# YTM32B1ME0 register map
Vendor: YTMicro; File version: 1.6
CPU: CM33 r0p4, little endian, MPU, FPU, 2 interrupt priority bits
Registers are 32-bit, read-write, reset 0x0 unless marked. A register's access mark holds for its fields unless they carry their own. Offsets are from the block's base; [hi:lo] are bit positions; {n}, {i} and the like mark numbered series; 'fields as' and 'values as' point back to an identical list.

## CAN0 (part 4 of 4) — FlexCAN module
Base 0x40030000; register names take the prefix CAN0_
0x974 RXIMR61 — The RX Individual Mask Registers are used to store the acceptance masks for ID filtering in Rx MBs and the Legacy Rx FIFO. When the Legacy Rx FIFO is disabled (CAN_MCR.RFEN is negated), an individual mask is provided for each available Rx mailbox on a one-to-one correspondence. When the Legacy Rx FIFO is enabled (CAN_MCR.RFEN is asserted), an individual mask is provided for each Legacy Rx FIFO ID Filter Table Element on a one-to-one correspondence depending on the setting of $ ewline$ CAN_CTRL2.RFFN (see \hyperref[legacy-rx-fifo]{"Legacy Rx FIFO"}). CAN_RXIMR0 stores the individual mask associated with either MB0 or ID Filter Table Element 0, CAN_RXIMR1 stores the individual mask associated with either MB1 or ID Filter Table Element 1, and so on. CAN_RXIMRn registers can only be accessed by the CPU when the FlexCAN is in Freeze mode; otherwise, they are blocked by hardware. The CAN_RXIMRn registers are not affected by reset. They are located in RAM and must be explicitly initialized prior to any reception. The CAN_RXIMRn registers are not available if parameter IRMQ_EN is 0.
  [31:0] MI — Each Individual Mask Bit masks the corresponding bit in both the mailbox filter and Legacy Rx FIFO ID Filter Table element in distinct ways. For mailbox filters, see the RXMGMASK register description. For Legacy Rx FIFO ID Filter Table elements, see the RXFGMASK register description. 0b - The corresponding bit in the filter is ``don't care". 1b - The corresponding bit in the filter is checked.
0x978 RXIMR62 — The RX Individual Mask Registers are used to store the acceptance masks for ID filtering in Rx MBs and the Legacy Rx FIFO. When the Legacy Rx FIFO is disabled (CAN_MCR.RFEN is negated), an individual mask is provided for each available Rx mailbox on a one-to-one correspondence. When the Legacy Rx FIFO is enabled (CAN_MCR.RFEN is asserted), an individual mask is provided for each Legacy Rx FIFO ID Filter Table Element on a one-to-one correspondence depending on the setting of $ ewline$ CAN_CTRL2.RFFN (see \hyperref[legacy-rx-fifo]{"Legacy Rx FIFO"}). CAN_RXIMR0 stores the individual mask associated with either MB0 or ID Filter Table Element 0, CAN_RXIMR1 stores the individual mask associated with either MB1 or ID Filter Table Element 1, and so on. CAN_RXIMRn registers can only be accessed by the CPU when the FlexCAN is in Freeze mode; otherwise, they are blocked by hardware. The CAN_RXIMRn registers are not affected by reset. They are located in RAM and must be explicitly initialized prior to any reception. The CAN_RXIMRn registers are not available if parameter IRMQ_EN is 0.
  fields as RXIMR61
0x97C RXIMR63 — The RX Individual Mask Registers are used to store the acceptance masks for ID filtering in Rx MBs and the Legacy Rx FIFO. When the Legacy Rx FIFO is disabled (CAN_MCR.RFEN is negated), an individual mask is provided for each available Rx mailbox on a one-to-one correspondence. When the Legacy Rx FIFO is enabled (CAN_MCR.RFEN is asserted), an individual mask is provided for each Legacy Rx FIFO ID Filter Table Element on a one-to-one correspondence depending on the setting of $ ewline$ CAN_CTRL2.RFFN (see \hyperref[legacy-rx-fifo]{"Legacy Rx FIFO"}). CAN_RXIMR0 stores the individual mask associated with either MB0 or ID Filter Table Element 0, CAN_RXIMR1 stores the individual mask associated with either MB1 or ID Filter Table Element 1, and so on. CAN_RXIMRn registers can only be accessed by the CPU when the FlexCAN is in Freeze mode; otherwise, they are blocked by hardware. The CAN_RXIMRn registers are not affected by reset. They are located in RAM and must be explicitly initialized prior to any reception. The CAN_RXIMRn registers are not available if parameter IRMQ_EN is 0.
  fields as RXIMR61
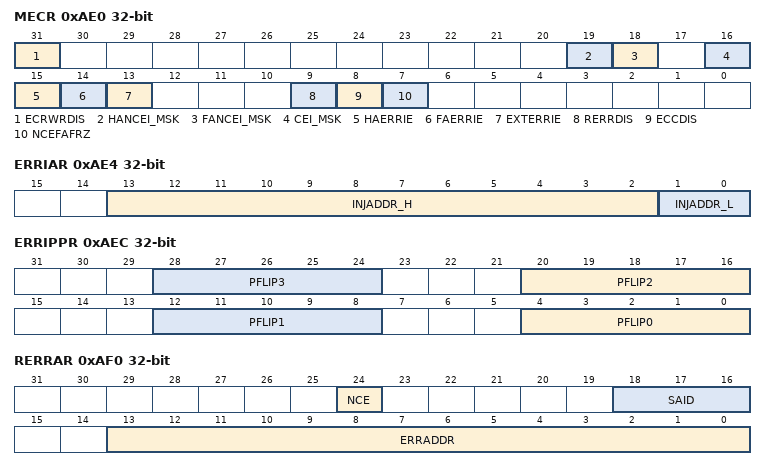
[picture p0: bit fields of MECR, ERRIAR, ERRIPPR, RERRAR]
0xAE0 MECR — The CAN_MECR register contains control bits for memory error detection and correction (ECC). NOTE: When CAN_CTRL2.ECRWRE is 0, writes to CAN_MECR are blocked, with the exception of the ECRWRDIS bit.
  [31] ECRWRDIS — ECRWRDIS is automatically set to 1 (disabled) when CTRL2.ECRWRE is asserted. The protocol described in \hyperref[detection-and-correction-of-memory-errors]{"Detection and Correction of Memory Errors"} must be followed.
    0=Write is enabled; 1=Write is disabled
  [19] HANCEI_MSK — Enables the interrupt in case of non-correctable errors detected in memory reads issued by the host (CPU).
    0=Interrupt is disabled; 1=Interrupt is enabled
  [18] FANCEI_MSK — Enables the interrupt in case of non-correctable errors detected in memory reads issued by the FlexCAN internal processes.
    0=Interrupt is disabled; 1=Interrupt is enabled
  [16] CEI_MSK — Enables the interrupt in case of correctable errors detected in memory reads issued by the host or FlexCAN internal processes.
    0=Interrupt is disabled; 1=Interrupt is enabled
  [15] HAERRIE — Enables the injection of errors only in memory reads issued by the host (CPU).
    0=Interrupt is disabled; 1=Interrupt is enabled
  [14] FAERRIE — Enables the injection of errors only in memory reads issued by the FlexCAN internal processes.
    0=Interrupt is disabled; 1=Interrupt is enabled
  [13] EXTERRIE — Memory accesses performed by internal FlexCAN processes are 64-bit accesses. EXTERRIE extends the error injection on 32-bit memory accesses to the complementary 32-bit word using the same 32-bit error injection data and parity words. See 'Error Injection Data Pattern Register (CAN_ERRIDPR)' and 'Error Injection Parity Pattern Register (CAN_ERRIPPR)'.
    0=Error injection is applied only to the 32-bit word; 1=Error injection is applied to the 64-bit word
  [9] RERRDIS — NOTE: When reading the report registers, RERRDIS must be set to ensure coherence on the consecutive register reads.
    0=Enable updates of the error report registers; 1=Disable updates of the error report registers. The update of error-related flags and the generation of bus transfer errors are still active.
  [8] ECCDIS — In addition to disabling the error report mechanism, ECCDIS = 1 also stops the update of the error-related flags and generation of bus transfer errors. The parity bits continue to be calculated and written into memory on write transactions.
    0=Enable memory error correction; 1=Disable memory error correction
  [7] NCEFAFRZ — Determines the response when a non-correctable error is detected in a memory read performed by FlexCAN internal processes.
    0=Keep normal operation; 1=Put FlexCAN in Freeze mode (according to \hyperref[freeze-mode]{"Freeze Mode"}). In this case, entering Freeze mode prevents corrupted data from being treated as valid by FlexCAN internal processes.
0xAE4 ERRIAR
  [13:2] INJADDR_H — Defines the twelve most significant bits of the physical RAM address where a memory read error is to be injected. See \hyperref[CAN-error-injection-address-mapping-for-maximum-configuration]{CAN error injection address mapping for maximum configuration}
  [1:0] INJADDR_L — Read-only field that defines the two least significant bits of the physical RAM address where a memory read error is to be injected. INJADDR_L[1:0] are always zero to ensure that the address is on a 32-bit boundary.
0xAE8 ERRIDPR — The CAN_ERRIDPR register holds the error pattern to be injected in the data word read from memory. The CAN_ERRIDPR register is not available when parameter ECC_EN is 0.
  [31:0] DFLIP — Bits set to 1 in the flip pattern cause the corresponding data bit in the word read from memory to invert.
0xAEC ERRIPPR — The CAN_ERRIPPR register holds the error pattern to be injected in parity bits read from memory along with data word. Bits set to 1 in the flip pattern cause the corresponding parity bit in the word read from memory to invert. The CAN_ERRIPPR register is not available when parameter ECC_EN is 0.
  [8n+4:8n] PFLIP{n} (n=0..3)
0xAF0 RERRAR — The CAN_RERRAR register reports the address used for an access in which an error (correctable or non-correctable) was detected, and reports the identification of the source of that access. The address is always reported using a 32-bit alignment. Non-aligned accesses ewline (CAN_ERRADDR[1:0] are non-0) are reported with the address aligned and data is reported in CAN_RERRDR accordingly shifted. In case of errors detected in accesses larger than 32-bit (as performed by FlexCAN internal processes), the address of the 32-bit word in which the error was detected is reported. In case of errors detected in more than one 32-bit word, only the least significant address is reported. The CAN_RERRAR register is not available when parameter ECC_EN is 0.
  [24] NCE ro — Indicates that the report is due to a noncorrectable error.
    0=Reporting a correctable-error; 1=Reporting a non-correctable error
  [18:16] SAID ro — SAID[2] - Identification of the requestor of the memory read request: • 0: Requested by FlexCAN internal processes • 1: Requested by host (CPU) SAID[1] - Details of FlexCAN operation: • 0: Move • 1: Scanning SAID[0] - Operation that requested the memory read: • 0: Transmission • 1: Reception
  [13:0] ERRADDR ro
0xAF4 RERRDR — The CAN_RERRDR register reports the raw data (unmodified by the correction performed by ECC logic) read from memory with error. The value reported does not represent the transient values of the BUSY bit when reading a message buffer (See \hyperref[CAN-message-buffer-code-for-RX-buffers]{CAN message buffer code for RX buffers}). The CAN_RERRDR register is not available when parameter ECC_EN is 0.
  [31:0] RDATA ro
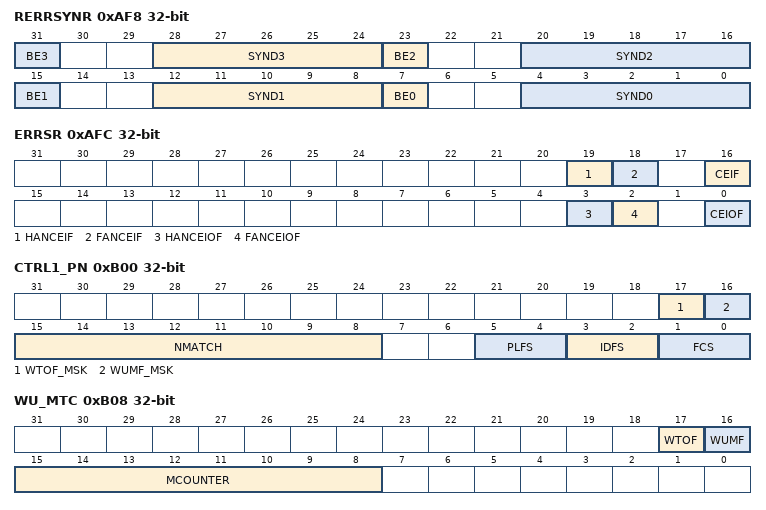
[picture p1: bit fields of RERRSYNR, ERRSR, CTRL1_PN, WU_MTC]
0xAF8 RERRSYNR
  [8n+7] BE{n} ro (n=0..3)
    0=The byte was not read; 1=The byte was read
  [28:24] SYND3 ro — See \hyperref[CAN-syndrome-definition]{CAN syndrome definition}.
  [20:16] SYND2 ro — See \hyperref[CAN-syndrome-definition]{CAN syndrome definition}.
  [12:8] SYND1 ro — See \hyperref[CAN-syndrome-definition]{CAN syndrome definition}.
  [4:0] SYND0 — See \hyperref[CAN-syndrome-definition]{CAN syndrome definition}.
0xAFC ERRSR — The CAN_ERRSR register holds the status bits of the error correction and detection operations. These flags can be cleared by writing 1 to them. Writing 0 has no effect. The CAN_ERRSR register is not available when parameter ECC_EN is 0.
  [19] HANCEIF — HANCEIF = 1 indicates that a non-correctable error was detected in a memory read initiated by the Hhost. A bus transfer error is asserted for that access. If CAN_MECR.HANCEI_MSK is set, the interrupt is asserted.
    0=No non-correctable errors were detected in host accesses so far; 1=A non-correctable error was detected in a host access
  [18] FANCEIF — FANCEIF = 1 indicates that a non-correctable error was detected in a memory read initiated by FlexCAN internal processes. If CAN_MECR.FANCEI_MSK is set, the interrupt is asserted.
    0=No non-correctable errors were detected in FlexCAN accesses so far; 1=A non-correctable error was detected in a FlexCAN access
  [16] CEIF — CEIF = 1 indicates that a correctable error was detected in a memory read. If CAN_MECR.CEI_MSK is set, the interrupt is asserted.
    0=No correctable errors were detected so far; 1=A correctable error was detected
  [3] HANCEIOF — HANCEIOF = 1 indicates that a non-correctable error was detected in a memory read initiated by the host when HANCEIF was set. No interrupt is associated with this flag. See \hyperref[error-indication]{"Error Indication"}.
    0=No overrun on non-correctable errors in host access; 1=Overrun on non-correctable errors in host access
  [2] FANCEIOF — FANCEIOF = 1 indicates that a non-correctable error was detected in a memory read initiated by FlexCAN internal processes when FANCEIF was set. No interrupt is associated with this flag. See \hyperref[error-indication]{"Error Indication"}.
    0=No overrun on non-correctable errors in FlexCAN access; 1=Overrun on non-correctable errors in FlexCAN access
  [0] CEIOF — CEIOF = 1 indicates that a correctable error was detected in a memory read when CEIF was set. No interrupt is associated with this flag. See \hyperref[error-indication]{"Error Indication"}.
    0=No overrun on correctable errors; 1=Overrun on correctable errors
0xB00 CTRL1_PN — The CAN_CTRL1_PN register contains control bits for Pretended Networking mode filtering selection. Configure CAN_CTRL1_PN with the filter criteria to be used to receive Wake Up messages. CAN_CTRL1_PN bits other than WTOF_MSK and WUMF_MSK can be written in Freeze mode only. The CAN_CTRL1_PN register is not available when parameter PNET_EN is 0.
  [17] WTOF_MSK — Masks the generation of a Wake Up event originated by a timeout
    0=Timeout Wake Up event is disabled; 1=Timeout Wake Up event is enabled
  [16] WUMF_MSK — Masks the generation of a Wake Up event originated by a successful filtered Rx message
    0=Wake Up match event is disabled; 1=Wake Up match event is enabled
  [15:8] NMATCH — Number of Messages Matching the Same Filtering Criteria NMATCH defines the number of times a given message must match the predefined filtering criteria for ID and/or PL before generating a Wake Up event. This quantity can be configured in the 1 to 255 range by using values from 0x01 to 0xFF, respectively
    1=Received message must match the predefined filtering criteria for ID and/or PL once before generating a Wake Up event; 2=Received message must match the predefined filtering criteria for ID and/or PL twice before generating a Wake Up event. ewline ......; 255=Received message must match the predefined filtering criteria for ID and/or PL 255 times before generating a Wake Up event
  [5:4] PLFS — Selects the level of payload filtering to be applied when FlexCAN is under Pretended Networking mode. Filtering does not accept remote messages (RTR=1) when payload filtering is active.
    0=Match upon a payload contents against an exact target value; 1=Match upon a payload value greater than or equal to a specified target value; 10=Match upon a payload value smaller than or equal to a specified target value; 11=Match upon a payload value inside a range, greater than or equal to a specified lower limit, and smaller than or equal to a specified upper limit
  [3:2] IDFS — In ID filtering, the IDE and RTR bits are also considered as part of the reception filter if the IDE_MSK and RTR_MSK bits in the CAN_FLT_ID2_IDMASK register are set.
    0=Match upon a ID contents against an exact target value; 1=Match upon a ID value greater than or equal to a specified target value; 10=Match upon a ID value smaller than or equal to a specified target value; 11=Match upon a ID value inside a range, greater than or equal to a specified lower limit, and smaller than or equal to a specified upper limit
  [1:0] FCS — See \hyperref[receive-process-under-pretended-networking-mode]{"Receive Process under Pretended Networking Mode"}) for additional details.
    0=Message ID filtering only; 1=Message ID filtering and payload filtering; 10=Message ID filtering occurring a specified number of times; 11=Message ID filtering and payload filtering a specified number of times
0xB04 CTRL2_PN — The CAN_CTRL2_PN register contains configuration bits for the timeout value under Pretended Networking mode. CAN_CTRL2_PN can be written in Freeze mode only. The CAN_CTRL2_PN register is not available when parameter PNET_EN is 0.
  [15:0] MATCHTO — Timeout for No Message Matching the Filtering Criteria MATCHTO defines a timeout value that generates a Wake Up event if CAN_MCR.PNET_EN is asserted. If the timeout counter reaches the target value when the FlexCAN is under Pretended Networking mode, a Wake Up event is generated. The timeout limit can be configured from 1 to 65535 to control an internal 16-bit up-count timer to produce a trigger upon reaching this configured value. The internal timer is incremented based on periodic time ticks, of which the period is 64 times the CAN Bit Time unit. When MATCHTO is 0x0000, the timeout is disabled.
0xB08 WU_MTC — The CAN_WU_MTC register contains Wake Up information related to the matching processes performed while the FlexCAN receives frames under Pretended Networking mode. The CAN_WU_MTC register is not available when parameter PNET_EN is 0.
  [17] WTOF — WTOF generates a Wake Up event if CAN_CTRL1_PN.WTOF_MSK is asserted.
    0=No Wake Up by timeout event detected; 1=Wake Up by timeout event detected
  [16] WUMF — Indicates whether the FlexCAN has detected a matching Rx incoming message that passed the filtering criteria specified in CAN_CTRL1_PN. WUMF generates a Wake Up event if CAN_CTRL1_PN.WUMF_MSK is asserted.
    0=No Wake Up by match event detected; 1=Wake Up by match event detected
  [15:8] MCOUNTER — Number of Matches while in Pretended Networking MCOUNTER reports the number of times a given message has matched the predefined filtering criteria for ID and/or PL before a Wake Up event. MCOUNTER is reset by the FlexCAN when it enters in Pretended Networking mode, and is not affected by soft reset.
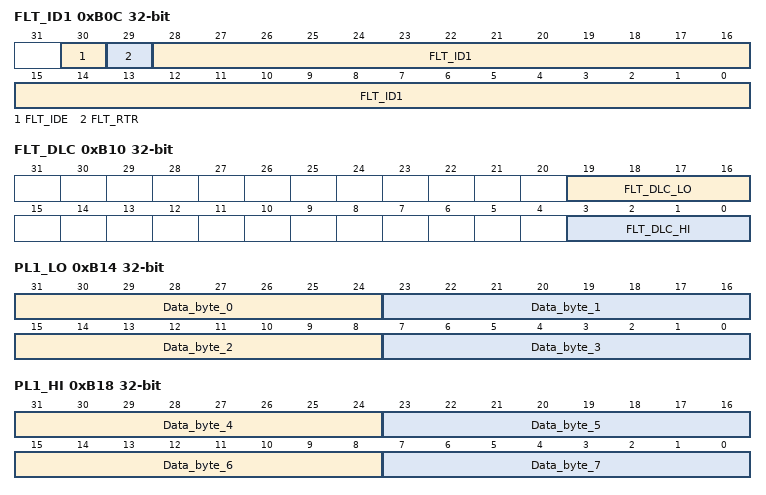
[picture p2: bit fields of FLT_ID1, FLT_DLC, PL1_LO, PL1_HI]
0xB0C FLT_ID1 — The CAN_FLT_ID1 register contains the FLT_ID1 target value and the IDE and RTR target values used to filter an incoming message ID. FLT_ID1 is used either for equal to, smaller than, greater than comparisons, or as the lower limit value in an ID range detection. CAN_FLT_ID1 can be written in Freeze mode only. The CAN_FLT_ID1 register is not available when parameter PNET_EN is 0.
  [30] FLT_IDE — FLT_IDE is used as part of the ID reception filter.
    0=Accept standard frame format; 1=Accept extended frame format
  [29] FLT_RTR — FLT_RTR is used as part of the ID reception filter.
    0=Reject remote frame (accept data frame); 1=Accept remote frame
  [28:0] FLT_ID1 — Defines either the 29 bits of an extended frame format, considering all bits, or the 11 bits of a standard frame format, considering just the 11 leftmost bits.
0xB10 FLT_DLC — The CAN_FLT_DLC register contains the DLC inside range target values (FLT_DLC_LO and FLT_DLC_HI) used to filter an incoming message. The DLC range is used only for payload filtering. CAN_FLT_DLC can be written in Freeze mode only. NOTE: When a fixed quantity of data bytes is required, both FLT_DLC_LO and FLT_DLC_HI need to be configured with the same value; otherwise, a range of DLC is considered for filtering (see \hyperref[receive-process-under-pretended-networking-mode]{"Receive Process under Pretended Networking Mode"}). The CAN_FLT_DLC register is not available when parameter PNET_EN is 0.
  [19:16] FLT_DLC_LO — Specifies the lower limit for the number of data bytes considered valid for payload comparison. FLT_DLC_LO is used as part of payload reception filter.
  [3:0] FLT_DLC_HI — Specifies the upper limit for the number of data bytes considered valid for payload comparison. FLT_DLC_HI is used as part of payload reception filter.
0xB14 PL1_LO — The CAN_PL1_LO register contains Payload Filter 1 low order bits of the target value used to filter incoming message payload. It is used either for “equal to”, “smaller than or equal to”, “greater than or equal to” comparisons, or as the lower limit value in a payload range detection. CAN_PL1_LO can be written in Freeze mode only. The CAN_PL1_LO register is not available when parameter PNET_EN is 0.
  [31-8n:24-8n] Data_byte_{n} (n=0..3) — Payload Filter 1 low order bits for Pretended Networking payload filtering corresponding to data byte {n}.
0xB18 PL1_HI — The CAN_PL1_HI register contains Payload Filter 1 high order bits of the target value used to filter incoming message payload. It is used either for “equal to”, “smaller than or equal to”, “greater than or equal to” comparisons, or as the lower limit value in a payload range detection. CAN_PL1_HI can be written in Freeze mode only. The CAN_PL1_HI register is not available when parameter PNET_EN is 0.
  [63-8n:56-8n] Data_byte_{n} (n=4..7) — Payload Filter 1 low order bits for Pretended Networking payload filtering corresponding to data byte {n}.
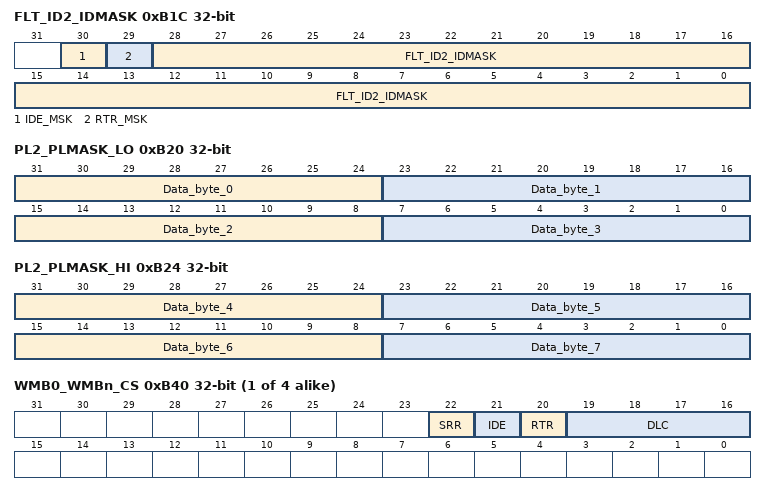
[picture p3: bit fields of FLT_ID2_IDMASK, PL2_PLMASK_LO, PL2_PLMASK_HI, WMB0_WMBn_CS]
0xB1C FLT_ID2_IDMASK — The CAN_FLT_ID2_IDMASK register contains the FLT_ID2 target value used only as the upper limit value in ID range detection. Also, when exact ID filtering criteria is selected, CAN_FLT_ID2_IDMASK is used to store the ID mask. The IDE_MSK and RTR_MSK bits are used in both ID filtering (exact and range) to enable FLT_IDE and FLT_RTR respectively to be used as part of ID reception filter. CAN_FLT_ID2_IDMASK can be written in Freeze mode only. The CAN_FLT_ID2_IDMASK register is not available when parameter PNET_EN is 0.
  [30] IDE_MSK
    0=The corresponding bit in the filter is “don’t care”; 1=The corresponding bit in the filter is checked
  [29] RTR_MSK — Remote Transmission Request Mask Bit – Indicates whether the frame type (data/remote) is part of the ID reception filter.
    values as IDE_MSK
  [28:0] FLT_ID2_IDMASK — ID Filter 2 for Pretended Networking Filtering / ID Mask Bits for Pretended Networking ID Filtering FLT_ID2_IDMASK is used as FLT_ID2 in range of ID filtering to define the ID filter value in either: • Extended frame format (29 bits), considering the FLT_ID2[28:0], or • Standard frame format (11 bits), considering the FLT_ID2[28:18]. Other bits in the [17:0] range have no meaning. FLT_ID2_IDMASK can also be used as IDMASK in exact ID filtering to define the mask value for either: • Extended frame format (29 bits), considering the IDMASK[28:0], or • Standard frame format (11 bits), considering the IDMASK[28:18]. Other bits in the [17:0] range have no meaning.
0xB20 PL2_PLMASK_LO — The CAN_PL2_PLMASK_LO register has two functions: • It contains the low order bits for the Payload Filter 2 used only as the upper limit value in a payload range detection. • When exact payload filtering criteria is selected, CAN_PL2_PLMASK_LO is used as the payload mask. Otherwise, CAN_PL2_PLMASK_LO is unused. CAN_PL2_PLMASK_LO can be written in Freeze mode only. The CAN_PL2_PLMASK_LO register is not available when parameter PNET_EN is 0.
  [31-8n:24-8n] Data_byte_{n} (n=0..3) — Payload Filter 2 low order bits / Payload Mask low order bits for Pretended Networking payload filtering corresponding to data byte {n}.
0xB24 PL2_PLMASK_HI — The CAN_PL2_PLMASK_HI register has two functions: • It contains the high order bits for the Payload Filter 2 used only as the upper limit value in a payload range detection. • When exact payload filtering criteria is selected, CAN_PL2_PLMASK_HI is used as the payload mask. Otherwise, CAN_PL2_PLMASK_HI is unused. CAN_PL2_PLMASK_HI can be written in Freeze mode only. The CAN_PL2_PLMASK_HI register is not available when parameter PNET_EN is 0.
  [63-8n:56-8n] Data_byte_{n} (n=4..7) — Payload Filter 2 high order bits / Payload Mask high order bits for Pretended Networking payload filtering corresponding to data byte {n}.
{0xB40+0x10*i} WMB{i}_WMBn_CS (i=0..3) — Each of the four WMBs contains a register to store the Control Status (C/S) information (IDE, RTR, and DLC fields) of an incoming Rx message. NOTE: The C/S registers are located at 0xB40 for WMB0, 0xB50 for WMB1, 0xB60 for WMB2, and 0xB70 for WMB3. The CAN_WMBn_CS registers are not available when parameter PNET_EN is 0.
  [22] SRR
  [21] IDE
    0=Frame format is standard; 1=Frame format is extended
  [20] RTR
    0=Frame is data frame (not remote); 1=Frame is a remote frame
  [19:16] DLC — Length of Data in Bytes – Length (in bytes) of the Rx data received when FlexCAN is in Pretended Networking mode. DLC is written by the FlexCAN module, copied from the DLC (Data Length Code) field of the received frame. The DLC field indicates which data bytes are valid.
{0xB44+0x10*i} WMB{i}_WMBn_ID (i=0..3) — Each of the four WMBs contains a register to store the ID information of an incoming Rx message. NOTE: The ID registers are located at 0xB44 for WMB0, 0xB54 for WMB1, 0xB64 for WMB2, and 0xB74 for WMB3. The CAN_WMBn_ID registers are not available when parameter PNET_EN is 0.
  [28:0] ID — Received ID under Pretended Networking Mode – Stores the received ID as either: • The 29 bits of the extended frame format (considering the ID[28:0] field), or • The 11 bits of the standard frame format (considering the ID[28:18] field only. The remaining bits in the ID[17:0] range have no meaning.
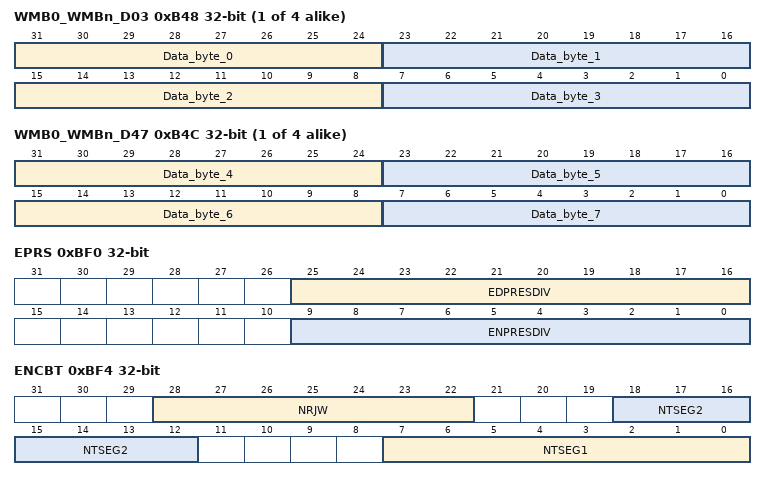
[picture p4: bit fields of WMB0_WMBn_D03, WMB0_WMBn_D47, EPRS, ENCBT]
{0xB48+0x10*i} WMB{i}_WMBn_D03 (i=0..3) — Each of the four WMBs contains a register to store the data bytes 0 to 3 of the payload information of an incoming Rx message. This register’s content is cleared when the incoming matched message is either a remote frame (RTR=1) or a data frame with DLC=0. NOTE: The Data 0-3 registers are located at 0xB48 for WMB0, 0xB58 for WMB1, 0xB68 for WMB2, and 0xB78 for WMB3. The CAN_WMBn_D03 registers are not available when parameter PNET_EN is 0.
  [31-8n:24-8n] Data_byte_{n} (n=0..3) — Received payload corresponding to data byte {n} under Pretended Networking mode.
{0xB4C+0x10*i} WMB{i}_WMBn_D47 (i=0..3) — Each of the four WMBs contains a register to store the data bytes 4 to 7 of the payload information of an incoming Rx message. This register’s content is cleared when the incoming matched message is either a remote frame (RTR=1) or a data frame with DLC=0. NOTE: The Data 4-7 registers are located at 0xB4C for WMB0, 0xB5C for WMB1, 0xB6C for WMB2, and 0xB7C for WMB3. The CAN_WMBn_D47 registers are not available when parameter PNET_EN is 0.
  [63-8n:56-8n] Data_byte_{n} (n=4..7) — Received payload corresponding to data byte {n} under Pretended Networking mode.
0xBF0 EPRS — The CAN_EPRS register defines the CAN bit timing prescalers for the nominal phase and data phase when CAN_CTRL2.BTE is set. CAN_EPRS is used by the hardware only if CAN_CTRL2.BTE is set; otherwise a write operation has no effect and all fields are read as zero. CAN_EPRS can be written only in Freeze mode because it is blocked by hardware in other modes. The contents of CAN_EPRS are not affected by soft reset. The CAN_EPRS register is not available when parameter CIA_BIT_TIMING is 0.
  [25:16] EDPRESDIV — EDPRESDIV defines the ratio between the PE clock frequency and the Serial Clock (Sclock) frequency in the data bit rate portion of a CAN FD message when CAN_CTRL2.BTE is set. The Sclock period defines the time quantum of the CAN FD protocol for the data bit rate. Sclock frequency = PE clock frequency / (EDPRESDIV + 1). NOTE: To minimize errors when processing FD frames, use the same value for ENPRESDIV and EDPRESDIV.
  [9:0] ENPRESDIV — ENPRESDIV defines the ratio between the PE clock frequency and the Serial Clock (Sclock) frequency for the nominal bit rate when CAN_CTRL2.BTE is set. The Sclock period defines the time quantum of the CAN protocol for the nominal phase. Sclock frequency = PE clock frequency / (ENPRESDIV + 1).
0xBF4 ENCBT — The CAN_ENCBT register provides an alternative way to store the CAN bit timing variables described in the CAN_CTRL1 and CAN_CBT registers, to achieve higher CAN bit timing resolution. CAN_ENCBT is used by the hardware only if CAN_CTRL2.BTE is set; otherwise a write operation has no effect and all fields are read as zero. CAN_ENCBT can be written only in Freeze mode because it is blocked by hardware in other modes. The contents of CAN_ENCBT are not affected by soft reset. The CAN_ENCBT register is not available when parameter CIA_BIT_TIMING is 0.
  [28:22] NRJW — NRJW defines the maximum number of time quanta that a nominal bit time can be changed by one resynchronization when CAN_CTRL2.BTE = 1. When CAN_CTRL2.BTE = 0, NRJW has no effect. One time quantum is equal to one Sclock period. Nominal Resynchronization Jump Width = NRJW + 1.
  [18:12] NTSEG2 — NTSEG2 defines the length of Time Segment 2 in the nominal bit time when CAN_CTRL2.BTE = 1. When CAN_CTRL2.BTE = 0, NTSEG2 has no effect. Nominal Time Segment 2 = (NTSEG2 + 1) × Time-Quanta Time-Quantum = one Sclock period
  [7:0] NTSEG1 — NTSEG1 defines the length of Time Segment 1 in the nominal bit time when CAN_CTRL2.BTE = 1. When CAN_CTRL2.BTE = 0, NTSEG1 has no effect. Nominal Time Segment 1 = (NTSEG1 + 1) × Time-Quanta Time-Quantum = one Sclock period
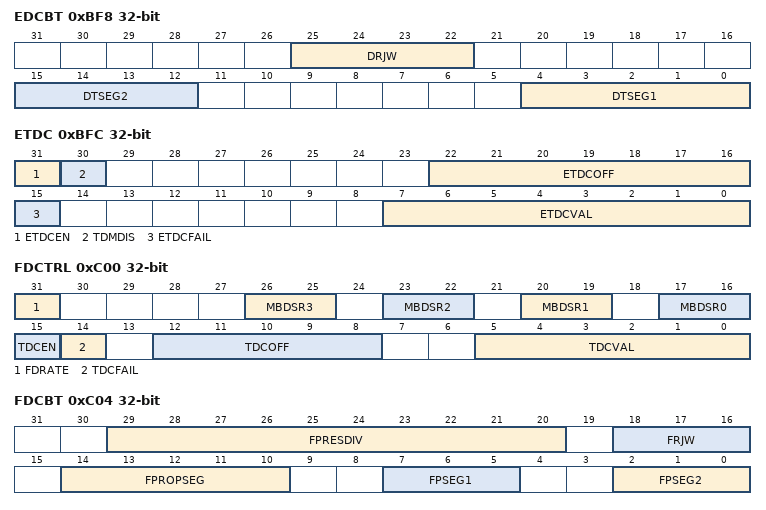
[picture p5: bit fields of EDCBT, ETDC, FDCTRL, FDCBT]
0xBF8 EDCBT — The CAN_EDCBT register provides an alternative way to store the data phase CAN bit timing variables described in the CAN_FDCBT register, to achieve higher CAN bit timing resolution. CAN_EDCBT is used by the hardware only if CAN_CTRL2.BTE is set; otherwise a write operation has no effect and all fields are read as zero. CAN_EDCBT can be written only in Freeze mode because it is blocked by hardware in other modes. The contents of CAN_EDCBT are not affected by soft reset. The CAN_EDCBT register is not available when parameter CIA_BIT_TIMING is 0. NOTE: CAN_EDCBT.DTSEG1 must be at least two time quanta.
  [25:22] DRJW — DRJW defines the maximum number of time quanta that a data phase bit time can be changed by one resynchronization when CAN_CTRL2.BTE = 1. When CAN_CTRL2.BTE = 0, DRJW has no effect. One time quantum is equal to one Sclock period. Data Phase Resynchronization Jump Width = DRJW + 1.
  [15:12] DTSEG2 — DTSEG2 defines the length of Time Segment 2 in the data phase bit time when CAN_CTRL2.BTE = 1. When CAN_CTRL2.BTE = 0, DTSEG2 has no effect. Data Phase Time Segment 2 = (DTSEG2 + 1) × Time-Quanta Time-Quantum = one Sclock period
  [4:0] DTSEG1 — DTSEG1 defines the length of Time Segment 1 in the data phase bit time when CAN_CTRL2.BTE = 1. When CAN_CTRL2.BTE = 0, DTSEG1 has no effect. Data Phase Time Segment 1 = (DTSEG1 + 1) × Time-Quanta Time-Quantum = one Sclock period
0xBFC ETDC — The CAN_ETDC register contains extended versions of the fields CAN_FDCTRL.TDCOFF and CAN_FDCTRL.TDCVAL. CAN_ETDC is used by the hardware only if CAN_CTRL2.BTE is set; otherwise a write operation has no effect and all fields are read as zero. The CAN_ETDC register is not available when parameter CIA_BIT_TIMING is 0. NOTE: See the transmitter delay compensation section of the CAN Protocol Standard (ISO 11898-1) for additional details.
  [31] ETDCEN — ETDCEN can be written in Freeze mode only. NOTE: TDC must be disabled when Loop-Back mode is enabled (see CAN_CTRL1.LPB).
    0=TDC is disabled; 1=TDC is enabled
  [30] TDMDIS — When TDC measurement is disabled, the secondary sample point position is determined only by the enhanced TDC offset (ETDCOFF) field. Otherwise, if TCD measurement is enabled, then the secondary sample point position is determined by the sum of the transceiver delay measurement plus the enhanced TDC offset. TDMDIS is not affected by soft reset. TDMDIS can be enabled only if CAN_CTRL2.BTE is set.
    0=TDC measurement is enabled; 1=TDC measurement is disabled
  [22:16] ETDCOFF — ETDCOFF contains the offset value to be added to the measured transceiver’s loop delay in order to define the position of the delayed comparison point when bit rate switching is active. See “Transceiver Delay Compensation” on page 187 for additional details on how the loop delay measurement is performed. ETDCOFF can be written in Freeze mode only. Its value is defined in protocol engine (PE) clock periods and must be selected to be smaller than the CAN bit duration in the data phase bit rate for proper operation. ETDCOFF must not be configured as zero. NOTE: If CAN_CTRL2.BTE is set after a chip-level hard reset, ETCDOFF is read as 0x1.
  [15] ETDCFAIL — ETDCFAIL indicates when the Transceiver Delay Compensation (TDC) mechanism is out of range, unable to compensate the transceiver's loop delay and successfully compare the delayed received bits to the transmitted ones ETDCFAIL is set the first time the FlexCAN detects the out of range condition. To clear ETDCFAIL, write 1 to it. See \hyperref[transceiver-delay-compensation]{"Transceiver Delay Compensation"}.
    0=Measured loop delay is in range; 1=Measured loop delay is out of range
  [7:0] ETDCVAL — ETDCVAL contains the ETDCOFF field added to the measured value of the transceiver loop delay in the latest transmitted CAN FD frame with BRS equal to recessive. ETDCVAL is only updated by the hardware if the ETDCEN bit is set. ETDCVAL is affected by soft reset. NOTE: If TDMDIS is set, ETDCVAL stores ETDCOFF only.
0xC00 FDCTRL
  [31] FDRATE — The CPU can write the FDRATE bit any time. However, its effect becomes active only when the CAN bus is in the Wait for Bus Idle, Bus Idle, or Bus Off state, or when the current frame under reception or transmission reaches the interframe space. By negating FDRATE, the CPU can force all bits in CAN FD messages to be transmitted in nominal bit rate, regardless of the value of the BRS bit of the Tx MBs.
    0=Transmit a frame in nominal rate. The BRS bit in the Tx MB has no effect.; 1=Transmit a frame with bit rate switching if the BRS bit in the Tx MB is recessive
  [3n+17:3n+16] MBDSR{n} (n=0..3) — For region R{n} of message buffers allocated in RAM: • 00: Selects 8 bytes per message buffer. • 01: Selects 16 bytes per message buffer. • 10: Selects 32 bytes per message buffer. • 11: Selects 64 bytes per message buffer. MBDSR{n} can be written in Freeze mode only.
  [15] TDCEN — TDCEN can be written in Freeze mode only. NOTE: TDC must be disabled when Loop-Back mode is enabled (see CAN_CTRL1.LPB). NOTE: If CAN_CTRL2.BTE =1, TDCEN is read as zero and a write operation has no effect.
    0=TDC is disabled; 1=TDC is enabled
  [14] TDCFAIL — TDCFAIL indicates when the Transceiver Delay Compensation (TDC) mechanism is out of range, unable to compensate the transceiver’s loop delay, and successfully compare the delayed received bits to the transmitted ones. TDCFAIL is set the first time the FlexCAN detects the out of range condition. To clear TDCFAIL, write 1 to it. See \hyperref[transceiver-delay-compensation]{Transceiver Delay Compensation}. NOTE: If CAN_CTRL2.BTE = 1, TDCFAIL is read as zero and a write operation has no effect.
    values as ETDC.ETDCFAIL
  [12:8] TDCOFF — TDCOFF contains the offset value to be added to the measured transceiver’s loop delay in order to define the position of the delayed comparison point when bit rate switching is active. See \hyperref[transceiver-delay-compensation]{Transceiver Delay Compensation} for more details on how the loop delay measurement is performed. TDCOFF can be written in Freeze mode only. Its value can be defined in PE clock periods and must be selected to be smaller than the CAN bit duration in the data bit rate for proper operation. NOTE: It is not recommended to use TDCOFF equal to zero. NOTE: If CAN_CTRL2.BTE = 1, TDCOFF is read as zero and a write operation has no effect.
  [5:0] TDCVAL ro — TDCVAL contains the value of the transceiver loop delay measured from the transmitted EDL to R0 transition edge to the respective received one added to the TDCOFF value. This value is an integer multiple of the PE clock period. See \hyperref[protocol-timing]{"Protocol Timing"} for more details on how the loop delay measurement is performed. NOTE: If CAN_CTRL2.BTE = 1, TDCVAL is read as zero.
0xC04 FDCBT — The CAN_FDCBT register stores the CAN bit timing variables used in the data phase of CAN FD messages when CAN_FDCTRL.FDRATE is set, compatible with CAN FD specification. FPRESDIV, FPROPSEG, FPSEG1, FPSEG2, and FRJW are used to define the time quantum duration, the number of time quanta per CAN bit, and the sample point position for the data bit rate portion of a CAN FD message with the BRS bit set. The contents of CAN_FDCBT are not affected by soft reset. NOTE: The sum of the Fast Propagation Segment (FPROPSEG) and Fast Phase Segment 1 (FPSEG1) must be at least two time quanta. NOTE: If CAN_CTRL2.BTE = 1, the CAN_FDCBT register is read as zero and a write operation has no effect. The CAN_FDCBT register is not available when parameter FD_EN is 0.
  [29:20] FPRESDIV — FPRESDIV defines the ratio between the PE clock frequency and the Serial Clock (Sclock) frequency in the data bit rate portion of a CAN FD message with the BRS bit set. The Sclock period defines the time quantum of the CAN FD protocol for the data bit rate. Sclock frequency = PE clock frequency / (FPRESDIV + 1). NOTE: To minimize errors when processing FD frames, use the same value for FPRESDIV and PRESDIV (in CAN_CBT or CAN_CTRL1). For more details, see \hyperref[can-fd-frames]{"CAN FD Frames"}. FPRESDIV can be written only in Freeze mode because it is blocked by hardware in other modes
  [18:16] FRJW — FRJW defines the maximum number of time quanta that a bit time can be changed by one re-synchronization in the data bit rate portion of a CAN FD message with the BRS bit set. Resync Jump Width = FSJW + 1. One time quantum is equal to the Sclock period. FRJW can be written only in Freeze mode because it is blocked by hardware in other modes.
  [14:10] FPROPSEG — FPROPSEG defines the length of the Propagation Segment in the bit time in the data bit rate portion of a CAN FD message with the BRS bit set. Propagation Segment Time = FPROPSEG × Time-Quanta Time-Quantum = one Sclock period FPROPSEG can be written only in Freeze mode because it is blocked by hardware in other modes.
  [7:5] FPSEG1 — FPSEG1 defines the length of Phase Segment 1 in the bit time in the data bit rate portion of a CAN FD message with the BRS bit set. Phase Segment 1 = (FPSEG1 + 1) × Time-Quanta Time-Quantum = one Sclock period FPSEG1 can be written only in Freeze mode because it is blocked by hardware in other modes.
  [2:0] FPSEG2 — FPSEG2 defines the length of Phase Segment 2 in the data bit rate portion of a CAN FD message with the BRS bit set. Phase Segment 2 = (FPSEG2 + 1) × Time-Quanta Time-Quantum = one Sclock period FPSEG2 can be written only in Freeze mode because it is blocked by hardware in other modes.
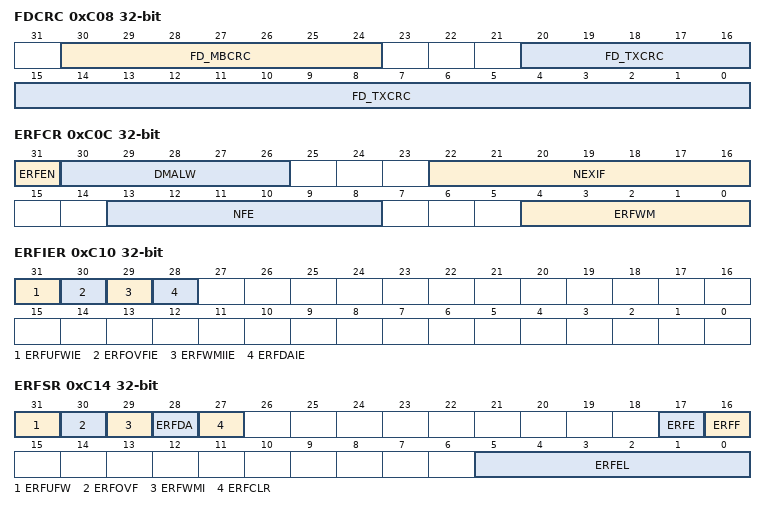
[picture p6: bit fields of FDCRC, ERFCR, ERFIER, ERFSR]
0xC08 FDCRC
  [30:24] FD_MBCRC — FD_MBCRC indicates the number of the mailbox corresponding to the value in the FD_TXCRC field, for both FD and non-FD frames. FD_MBCRC reports the same information as in the CAN_CRCR.MBCRC bit field.
  [20:0] FD_TXCRC ro — FD_TXCRC contains the CRC value calculated over the most recent transmitted message. Different CRC polynomials are used for different frame formats. A 15-bit polynomial, CRC_15, is used for all frames in CAN format. The second 17-bit polynomial, CRC_17, is used for frames in CAN FD format with a data field up to sixteen bytes long. The third 21-bit polynomial, CRC_21, is used for frames in CAN FD format with a data field longer than sixteen bytes. For CRC_15 and CRC_17, the 6 most significant bits and the 4 most significant bits are reported as zeros, respectively. For CRC_15, this register has the same content as CAN_CRCR.
0xC0C ERFCR — The CAN_ERFCR register is not available when parameter ERX_FIFO_EN is 0.
  [31] ERFEN — ERFEN can be written only in Freeze mode because it is blocked by hardware in other modes. NOTE: ERFEN must not be set if CAN_MCR.RFEN is set.
    0=Enable Enhanced Rx FIFO; 1=Disable Enhanced Rx FIFO
  [30:26] DMALW — Table \hyperref[CAN-DMALW-value-and-number-of-enhanced-RX-FIFO-elements-transferred]{"CAN DMALW value and number of enhanced RX FIFO elements transferred"} shows the number of elements and the last address for each Enhanced Rx FIFO element according to the value of DMALW. DMALW values not shown in Table \hyperref[CAN-DMALW-value-and-number-of-enhanced-RX-FIFO-elements-transferred]{"CAN DMALW value and number of enhanced RX FIFO elements transferred"} are reserved and must not be used. DMALW can be written only in Freeze mode because it is blocked by hardware in other modes.
  [22:16] NEXIF — NEXIF must be less than or equal to NFE + 1. The number of standard ID filter elements can be determined by the following equation: Number of Standard ID Filter Elements = 2 x (NFE - NEXIF +1) \hyperref[CAN-NEXIF-value-and-number-of-extended-or-standard-ID-filter-elements]{"CAN NEXIF value and number of extended or standard ID filter elements"} shows the number of extended ID filters and standard ID filters available for Enhanced Rx FIFO if all the filter elements are used. NEXIF can be written only in Freeze mode because it is blocked by hardware in other modes.
  [13:8] NFE — NFE can be written only in Freeze mode because it is blocked by hardware in other modes.
  [4:0] ERFWM — Minimum number of CAN messages = ERFWM + 1. When ERFWM + 1 is reached, ERFSR.ERFWMI is set. ERFWM can be written only in Freeze mode because it is blocked by hardware in other modes.
0xC10 ERFIER — The CAN_ERFIER register is not available when parameter ERX_FIFO_EN is 0.
  [31] ERFUFWIE
    0=Disable Enhanced Rx FIFO underflow interrupt; 1=Enable Enhanced Rx FIFO underflow interrupt
  [30] ERFOVFIE
    0=Disable Enhanced Rx FIFO overflow interrupt; 1=Enable Enhanced Rx FIFO overflow interrupt
  [29] ERFWMIIE
    0=Disable Enhanced Rx FIFO watermark interrupt; 1=Enable Enhanced Rx FIFO watermark interrupt
  [28] ERFDAIE
    0=Disable Enhanced Rx FIFO data available interrupt; 1=Enable Enhanced Rx FIFO data available interrupt
0xC14 ERFSR — The CAN_ERFSR register is not available when parameter ERX_FIFO_EN is 0.
  [31] ERFUFW — ERFUFW is cleared by writing 1 to it.
    0=Enhanced Rx FIFO underflow has not occurred; 1=Enhanced Rx FIFO underflow has occurred. Interrupt ipi_int_erfufw is asserted if CAN_ERFIER.ERFUFWIE = 1.
  [30] ERFOVF — ERFOVF is cleared by writing 1 to it.
    0=Enhanced Rx FIFO overflow has not occurred; 1=Enhanced Rx FIFO overflow has occurred. Interrupt ipi_int_erfovf is asserted if CAN_ERFIER.ERFOVFIE = 1.
  [29] ERFWMI — ERFWMI is cleared by writing 1 to it.
    0=The number of messages in the Enhanced Rx FIFO is not greater than the watermark; 1=The number of messages in the Enhanced Rx FIFO is greater than the watermark. Interrupt ipi_int_erfwm is asserted if CAN_ERFIER.ERFWMIIE = 1.
  [28] ERFDA — ERFDA is cleared by writing 1 to it.
    0=There is no message stored in the Enhanced Rx FIFO; 1=There is at least one message stored in the Enhanced Rx FIFO. Interrupt ipi_int_erfda is asserted if CAN_ERFIER.ERFDAIE = 1.
  [27] ERFCLR — Writing 1 to ERFCLR when the FlexCAN is in Freeze mode clears the Enhanced Rx FIFO content. Writing 0 to ERFCLR or writing to ERFCLR when the FlexCAN is not in Freeze mode has no effect.
  [17] ERFE ro
    0=The Enhanced Rx FIFO is not empty; 1=The Enhanced Rx FIFO is empty
  [16] ERFF ro
    0=The Enhanced Rx FIFO is not full; 1=The Enhanced Rx FIFO is full
  [5:0] ERFEL ro
{0xC30+4i} HR_TIME_STAMPn{i} (i=0..127)
  [31:0] TS — Capture of 32-bit timer value for the corresponding message buffer. The capture point depends on the value of CAN_CTRL2.TSTAMPCAP, as shown in \hyperref[CAN-high-resolution-time-stamp-register-operation]{"CAN high resolution time stamp register operation"}.
{0x3000+4i} ERFFELn{i} (i=0..127) — The Enhanced Rx FIFO Filter Element Registers are used to store the filter elements of the Enhanced Rx FIFO. For standard ID filtering, each CAN_ERFFELn register stores one filter element. For extended ID filtering, each pair of CAN_ERFFELn registers stores one filter element. CAN_ERFFELn registers can only be accessed by the CPU when the FlexCAN is in Freeze mode; otherwise, they are blocked by hardware. The CAN_ERFFELn registers are not affected by reset. They are located in RAM and must be explicitly initialized prior to any reception. The CAN_ERFFELn registers are not available if parameter ERX_FIFO_EN is 0.
  [31:0] FEL — Each filter element is used during the match process and, if the matching criteria are met, a message is stored in the Enhanced Rx FIFO.

## CAN1 (part 4 of 4) — FlexCAN module
Base 0x40034000; register names take the prefix CAN1_
Registers as CAN0.

## CAN2 (part 4 of 4) — FlexCAN module
Base 0x40038000; register names take the prefix CAN2_
Registers as CAN0.

## CAN3 (part 4 of 4) — FlexCAN module
Base 0x4003C000; register names take the prefix CAN3_
Registers as CAN0.

## CAN4 (part 4 of 4) — FlexCAN module
Base 0x4003D000; register names take the prefix CAN4_
Registers as CAN0.

## CAN5 (part 4 of 4) — FlexCAN module
Base 0x4003E000; register names take the prefix CAN5_
Registers as CAN0.
